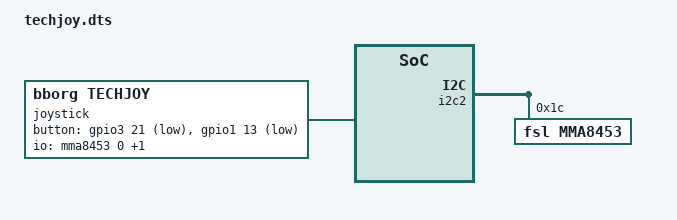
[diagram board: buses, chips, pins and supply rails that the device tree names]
/*
 * Techlab Cape joystick overlay
 *
 * Copyright 2019 Konsulko Group
 * Matt Porter <mporter@konsulko.com>
 *
 * This program is free software; you can redistribute it and/or
 * modify it under the terms of the GNU General Public License as
 * published by the Free Software Foundation version 2.
 *
 * This program is distributed "as is" WITHOUT ANY WARRANTY of any
 * kind, whether express or implied; without even the implied warranty
 * of MERCHANTABILITY or FITNESS FOR A PARTICULAR PURPOSE.  See the
 * GNU General Public License for more details.
 */

/dts-v1/;
/plugin/;

#include <dt-bindings/gpio/gpio.h>

/ {
	fragment@0 {
		target = <&i2c2>;
		__overlay__ {
			#address-cells = <1>;
			#size-cells = <0>;
			mma8453: mma8453@1c {
				#io-channel-cells = <1>;
				status = "okay";
				compatible = "fsl,mma8453";
				reg = <0x1c>;
			};

		};
	};

	fragment@1 {
		target = <&ocp>;
		__overlay__ {
			P2_33_pinmux { status = "disabled"; };	/* Left - gpio3_21 */
			P1_29_pinmux { status = "disabled"; };	/* Right - gpio1_13 */
			cape-universal { status = "disabled"; };

			joystick {
				compatible = "bborg,techjoy";
				pinctrl-0 = <&P2_33_gpio_input_pin>,
					    <&P1_29_gpio_input_pin>;
				io-channels = <&mma8453 0>, <&mma8453 1>;
				io-channel-names = "accel_x", "accel_y";
				button-gpios = <&gpio3 21 GPIO_ACTIVE_LOW>,
					       <&gpio1 13 GPIO_ACTIVE_LOW>;
			};
		};
	};
};
